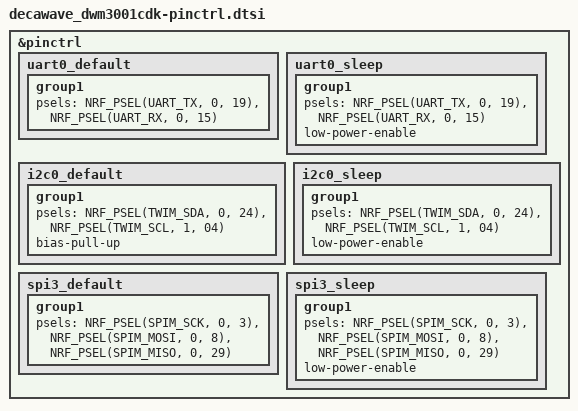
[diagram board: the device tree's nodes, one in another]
/*
 * Copyright (c) 2022 Nordic Semiconductor
 * SPDX-License-Identifier: Apache-2.0
 */

&pinctrl {
	uart0_default: uart0_default {
		group1 {
			psels = <NRF_PSEL(UART_TX, 0, 19)>,
				<NRF_PSEL(UART_RX, 0, 15)>;
		};
	};

	uart0_sleep: uart0_sleep {
		group1 {
			psels = <NRF_PSEL(UART_TX, 0, 19)>,
				<NRF_PSEL(UART_RX, 0, 15)>;
			low-power-enable;
		};
	};

	i2c0_default: i2c0_default {
		group1 {
			psels = <NRF_PSEL(TWIM_SDA, 0, 24)>,
				<NRF_PSEL(TWIM_SCL, 1, 04)>;
			bias-pull-up;
		};
	};

	i2c0_sleep: i2c0_sleep {
		group1 {
			psels = <NRF_PSEL(TWIM_SDA, 0, 24)>,
				<NRF_PSEL(TWIM_SCL, 1, 04)>;
			low-power-enable;
		};
	};

	spi3_default: spi3_default {
		group1 {
			psels = <NRF_PSEL(SPIM_SCK, 0, 3)>,
				<NRF_PSEL(SPIM_MOSI, 0, 8)>,
				<NRF_PSEL(SPIM_MISO, 0, 29)>;
		};
	};

	spi3_sleep: spi3_sleep {
		group1 {
			psels = <NRF_PSEL(SPIM_SCK, 0, 3)>,
				<NRF_PSEL(SPIM_MOSI, 0, 8)>,
				<NRF_PSEL(SPIM_MISO, 0, 29)>;
			low-power-enable;
		};
	};
};
